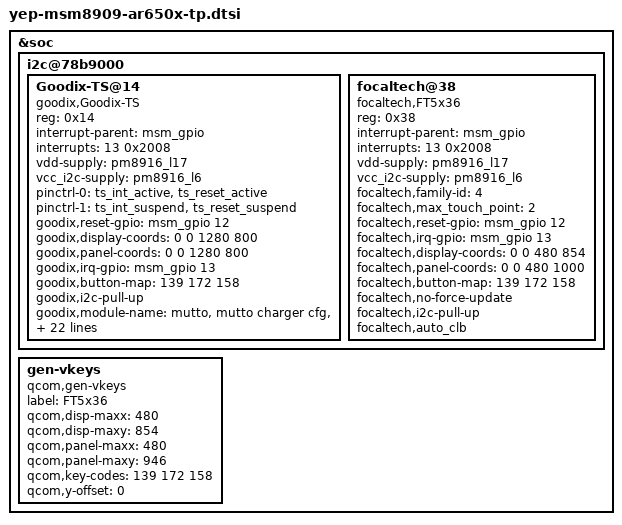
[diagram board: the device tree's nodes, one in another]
/* Copyright (c) 2013, The Linux Foundation. All rights reserved.
 *
 * it under the terms of the GNU General Public License version 2 and
 * only version 2 as published by the Free Software Foundation.
 *
 * This program is distributed in the hope that it will be useful,
 * but WITHOUT ANY WARRANTY; without even the implied warranty of
 * MERCHANTABILITY or FITNESS FOR A PARTICULAR PURPOSE.  See the
 * GNU General Public License for more details.
 */

/*
 * As a general rule, only version-specific property overrides should be placed
 * inside this file. However, device definitions should be placed inside the
 * yep_product_ql1001_flatform.dtsi file.
 */
 
/*  
    Date    		Author    	   	Module         Sensor_id     Old_ver   New_ver
  2014-01-12        litao2          NULL		     0			 
  2015-06-08	   shihuijun	   xingqihong	     5	          V65      V66
      
  2015-08-11	   shihuijun	     mutto           0	          NULL     0X41
  2015-08-30       shihuijun         mutto           0            0x41     0x42
  
  2015-08-11	   shihuijun	 xqh charger cfg     6	          NULL     0X41
  
  2018-08-30       shihuijun     mutto charger cfg   1            MULL     0x42 
*/

/*  Date            Author         	 				Why
   2015-05-18      yuquan        		           creat
*/
&soc {

		i2c@78b9000 { /* BLSP1 QUP5 */
		Goodix-TS@14 {
			compatible = "goodix,Goodix-TS";
			reg = <0x14>;
			interrupt-parent = <&msm_gpio>;
			interrupts = <13 0x2008>;
			vdd-supply = <&pm8916_l17>;
			vcc_i2c-supply = <&pm8916_l6>;
			/* pins used by touchscreen start add by zengguang 2014.7.15*/
			pinctrl-names = "pmx_ts_active","pmx_ts_suspend";
			pinctrl-0 = <&ts_int_active &ts_reset_active>;
			pinctrl-1 = <&ts_int_suspend &ts_reset_suspend>;
			/* pins used by touchscreen end add by zengguang 2014.7.15*/
			goodix,reset-gpio = <&msm_gpio 12 0x00>;
			goodix,display-coords = <0 0 1280 800>;
			goodix,panel-coords = <0 0 1280 800>;
			goodix,irq-gpio = <&msm_gpio 13 0x00>;
			goodix,button-map = <139 172 158>;
			goodix,i2c-pull-up;
			goodix,module-name = "mutto","mutto charger cfg","unknow","unknow","unknow","xingqihong","xingqihong charger cfg","unknow";
			
			/*GT915L,QL650x mutto panel cfg*/
			goodix,cfg-data0 = [
42 20 03 00 05 0A 35 20 01 C8 
28 08 55 46 0F 05 00 00 00 00 
00 00 00 14 14 24 14 95 35 FF 
18 1A 1E 14 00 00 00 22 04 1D 
00 00 00 00 00 00 00 00 00 00 
00 14 3C 54 C5 03 08 00 00 04 
79 16 00 6C 1B 00 62 22 00 5D 
2B 00 5A 36 00 5A 00 00 00 00 
00 00 00 00 00 00 00 00 00 00 
00 00 00 00 00 00 00 00 00 00 
00 00 00 00 00 00 00 00 00 00 
00 00 1D 1C 1B 1A 19 18 17 16 
15 14 13 12 11 10 0F 0E 0D 0C 
0B 0A 09 08 07 06 05 04 03 02 
01 00 00 01 02 03 04 05 06 07 
08 09 0A 0B 0C 0D 0E 0F 10 11 
12 13 14 15 16 17 18 19 1B 1C 
1D 1E 1F 20 21 22 23 24 25 26 
27 28 29 2A 1B 01];

			/*GT915L,QL650x mutto charger cfg*/
			goodix,cfg-data1 = [
42 20 03 00 05 0A 35 20 01 C8 
28 08 55 46 0F 05 00 00 00 00 
00 00 00 14 14 24 14 95 35 FF 
18 1A 1E 14 00 00 00 42 04 1D 
00 00 00 00 00 00 00 00 00 00 
00 14 3C 94 C5 03 08 00 00 04 
79 16 00 6C 1B 00 62 22 00 5D 
2B 00 5A 36 00 5A 00 00 00 00 
00 00 00 00 00 00 00 00 00 00 
00 00 00 00 00 00 00 00 00 00 
00 00 00 00 00 00 00 00 00 00 
50 00 1D 1C 1B 1A 19 18 17 16 
15 14 13 12 11 10 0F 0E 0D 0C 
0B 0A 09 08 07 06 05 04 03 02 
01 00 00 01 02 03 04 05 06 07 
08 09 0A 0B 0C 0D 0E 0F 10 11 
12 13 14 15 16 17 18 19 1B 1C 
1D 1E 1F 20 21 22 23 24 25 26 
27 28 29 2A 6B 01];

			/*gt915,huaxingda module panel*/
			goodix,cfg-data2 = [
00 D0 02 00 05 05 05 01 01 08 
1E 05 50 3C 03 05 00 00 00 00 
00 00 f3 00 00 00 00 8C 0E 0E 
38 00 B9 08 00 00 00 9B 03 1D 
00 00 00 00 00 00 00 00 00 00 
00 24 64 94 C5 02 05 00 00 04 
AF 28 00 90 31 00 78 3C 00 64 
49 00 53 5A 00 53 18 38 60 00 
F7 50 38 99 99 27 00 00 00 00 
00 00 00 00 00 00 00 00 00 00 
00 00 00 00 00 00 00 00 00 00 
00 00 02 04 06 08 0A 0C 0E 10 
12 14 16 18 1A 1C 00 00 00 00 
00 00 00 00 00 00 00 00 00 00 
00 00 00 14 13 12 10 0F 0C 0A 
08 06 04 02 16 18 1C 1D 1E 1F 
20 21 22 24 26 28 29 2A 00 00 
00 00 00 00 00 00 00 00 00 00 
00 00 00 00 82 01];

 			
/*GT915L,QL650x xingqihong panel cfg*/
 			goodix,cfg-data5 =[
42 20 03 00 05 0A 35 20 01 C8 
28 08 55 46 0F 05 00 00 00 00 
00 00 00 14 14 20 14 95 35 FF 
18 1A 1E 14 00 00 00 22 04 1D 
00 00 00 00 00 00 00 00 00 00 
00 14 3C 4A C5 03 08 00 00 04 
95 16 00 82 1B 00 70 22 00 64 
2B 00 5B 36 00 5B 00 00 00 00 
00 00 00 00 00 00 00 00 00 00 
00 00 00 00 00 00 00 00 00 00 
00 00 00 00 00 00 00 00 00 00 
00 00 00 01 02 03 04 05 06 07 
08 09 0A 0B 0C 0D 0E 0F 10 11 
12 13 14 15 16 17 18 19 1A 1B 
1C 1D 00 01 02 03 04 05 06 07 
08 09 0A 0B 0C 0D 0E 0F 10 11 
12 13 14 15 16 17 18 19 1B 1C 
1D 1E 1F 20 21 22 23 24 25 26 
27 28 29 2A E0 01
];

/*GT915L,QL650x xingqihong charger cfg*/
 			goodix,cfg-data6 =[
41 20 03 00 05 0A 35 20 02 C8 
28 0F 64 3C 0F 05 00 00 00 00 
00 00 04 14 14 20 14 95 35 FF 
17 19 C4 10 00 00 00 43 03 1D 
00 00 00 00 00 00 00 00 00 00 
00 0F 32 8A C5 03 00 00 00 04 
92 11 00 80 15 00 6F 1B 00 63 
23 00 5C 2C 00 5C 00 00 00 00 
00 00 00 00 00 00 00 00 00 00 
00 00 00 00 00 00 00 00 00 00 
00 00 00 00 00 00 00 00 00 00 
00 00 00 01 02 03 04 05 06 07 
08 09 0A 0B 0C 0D 0E 0F 10 11 
12 13 14 15 16 17 18 19 1A 1B 
1C 1D 00 01 02 03 04 05 06 07 
08 09 0A 0B 0C 0D 0E 0F 10 11 
12 13 14 15 16 17 18 19 1B 1C 
1D 1E 1F 20 21 22 23 24 25 26 
27 28 29 2A 10 01
];
			/*modified for shenyue hall cfg*/
 			goodix,cfg-data8 =[
43 D0 02 94 02 05 31 00 01 0F 
3C 08 50 37 03 05 00 00 00 00 
11 20 06 17 1A 1D 14 8C 01 0E 
39 00 18 1A 00 00 00 9C 04 9D 
00 01 00 00 00 00 00 08 0A 00 
00 2D 46 94 C5 02 07 00 00 04 
8A 2F 00 85 33 00 80 38 00 7D 
3D 00 7B 43 00 7B 00 00 00 00 
00 00 00 00 00 00 00 00 00 00 
00 00 00 00 00 00 00 00 00 00 
00 00 00 00 00 00 00 00 00 00 
00 00 02 04 06 08 0A 0C 0E 10 
12 14 16 18 1A 1C 00 00 00 00 
00 00 00 00 00 00 00 00 00 00 
00 00 2A 29 28 26 24 22 21 20 
1F 1E 1D 1C 18 FF FF FF FF FF 
FF FF FF FF FF FF FF FF 00 00 
00 00 00 00 00 00 00 00 00 00 
00 00 00 00 DF 01
];

/*modified for shenyue fast param cfg begin by zhangdangku 2015.01.29*/

			/* normal high sensitivity */
			goodix,cfg-data10 =[
41 D1 02 01 05 05 35 30 01 C8 
26 08 46 32 03 05 00 00 FF 67 
12 11 00 17 19 1E 14 8C 2E 0E 
6E 70 D3 07 0A 14 00 02 32 11 
03 04 00 00 00 00 00 08 0A 00 
19 37 87 94 D5 88 08 00 26 04 
DB 3C 00 BD 48 00 A5 56 00 92 
67 00 83 7B 00 83 00 00 00 00 
00 00 00 00 00 00 00 00 00 00 
50 00 00 50 3C 26 00 00 00 06 
10 32 85 0C 53 00 00 19 00 00 
46 3C 02 04 06 08 0A 0C 0E 10 
12 14 16 18 1A 1C 00 00 00 00 
00 00 00 00 00 00 00 00 00 00 
00 00 2A 29 28 26 24 22 21 20 
1F 1E 1D 1C 18 16 14 13 12 10 
0F 0C 0A 08 06 04 02 00 00 00 
00 00 00 00 00 00 00 00 00 00 
00 00 00 00 AA 01			
];
/*modified for shenyue fast param cfg end by zhangdangku 2015.01.29*/

			/*modified for mutto charge cfg*/
 			goodix,cfg-data7 =[
43 D1 02 01 05 05 35 30 01 C8 
26 08 5A 46 03 05 00 00 FF 67 
12 11 03 17 19 1E 14 8C 2E 0E 
C0 C2 31 0D 00 00 00 02 32 91 
00 04 00 00 00 00 00 08 0A 00 
19 B5 CF 94 D5 88 08 00 26 04 
7C B7 00 7E BC 00 80 C1 00 82 
C6 00 85 CC 00 85 00 00 00 00 
00 00 00 00 00 00 00 00 00 00 
00 00 00 00 00 00 00 00 00 06 
00 00 00 00 53 00 00 19 00 00 
46 3C 02 04 06 08 0A 0C 0E 10 
12 14 16 18 1A 1C 00 00 00 00 
00 00 00 00 00 00 00 00 00 00 
00 00 2A 29 28 26 24 22 21 20 
1F 1E 1D 1C 18 16 00 02 04 06 
08 0A 0C 0F 10 12 13 14 00 00 
00 00 00 00 00 00 00 00 00 00 
00 00 00 00 EA 01
];
			/*modified for mutto hall cfg*/
 			goodix,cfg-data9 =[
43 D0 02 94 02 05 31 00 01 CA 
3C 0F 5A 3C 03 05 00 00 00 00 
11 20 06 17 1A 1D 14 8C 01 0E 
B6 00 D3 07 00 00 00 9B 03 9D 
00 01 00 33 00 00 00 08 0A 00 
00 96 C8 94 C5 02 07 00 00 00 
8A 9A 00 86 A3 00 82 AD 00 7F 
B7 00 7C C2 00 7C 00 00 00 00 
00 00 00 00 00 00 00 00 00 00 
00 00 00 50 3C 50 1E 00 00 00 
00 00 00 00 00 00 00 00 00 00 
00 00 02 04 06 08 0A 0C 0E 10 
12 14 16 18 1A 1C 00 00 00 00 
00 00 00 00 00 00 00 00 00 00 
00 00 2A 29 28 26 24 22 21 20 
1F 1E 1D 1C 18 FF FF FF FF FF 
FF FF FF FF FF FF FF FF 00 00 
00 00 00 00 00 00 00 00 00 00 
00 00 00 00 87 01
];
				
/*modified for mutto fast param cfg begin by zhangdangku 2015.01.29*/

			/* normal high sensitivity */
			goodix,cfg-data11 =[
41 00 05 20 03 0A 3D 00 01 08
28 05 50 32 03 00 00 00 00 00 
00 00 00 18 1A 1C 14 95 35 FF 
2B 2D 1E 14 00 00 00 03 03 1D 
00 00 00 00 00 00 00 00 00 00 
00 14 64 94 C5 02 07 00 00 04 
B8 17 00 95 20 00 7D 2D 00 71 
3E 00 70 56 00 70 00 00 00 00 
00 00 00 00 00 00 00 00 00 00 
00 00 00 00 00 00 00 00 00 00 
00 00 00 00 00 00 00 00 00 00 
00 00 00 01 02 03 04 05 06 07 
08 09 0A 0B 0C 0D 0E 0F 10 11 
12 13 14 15 16 17 18 19 1A 1B 
1C 1D 00 01 02 03 04 05 06 07 
08 09 0A 0B 0C 0D 0E 0F 10 11 
12 13 14 15 16 17 18 19 1B 1C 
1D 1E 1F 20 21 22 23 24 25 26 
27 28 29 2A AC 01
];
/*modified for mutto fast param cfg end by zhangdangku 2015.01.29*/
};

		
		focaltech@38 {
			compatible = "focaltech,FT5x36";
			reg = <0x38>;
			interrupt-parent = <&msm_gpio>;
			interrupts = <13 0x2008>;
			vdd-supply = <&pm8916_l17>;
			vcc_i2c-supply = <&pm8916_l6>;
			focaltech,family-id = <4>;
			focaltech,max_touch_point = <2>;
			focaltech,reset-gpio = <&msm_gpio 12 0x00>;
			focaltech,irq-gpio = <&msm_gpio 13 0x00>;
			focaltech,display-coords = <0 0 480 854>;
			focaltech,panel-coords = <0 0 480 1000>;
			focaltech,button-map= <139 172 158>;
			focaltech,no-force-update;
			focaltech,i2c-pull-up;
			focaltech,auto_clb;
		};
	};
	gen-vkeys {
		compatible = "qcom,gen-vkeys";
		label = "FT5x36";
		qcom,disp-maxx = <480>;
		qcom,disp-maxy = <854>;
		qcom,panel-maxx = <480>;
		qcom,panel-maxy = <946>;
		qcom,key-codes = <139 172 158>;
		qcom,y-offset = <0>;
	};
};

